# TMS320F280049 register map
Vendor: Texas Instruments; Series: C2000 F28004x; File version: 0.2.0-generated
Registers are 16-bit, read-write, reset 0x0 unless marked. A register's access mark holds for its fields unless they carry their own. Offsets are from the block's base; [hi:lo] are bit positions; {n}, {i} and the like mark numbered series.

## PIECTRLREGS — PIE CTRL Registers
Base 0x000019C0
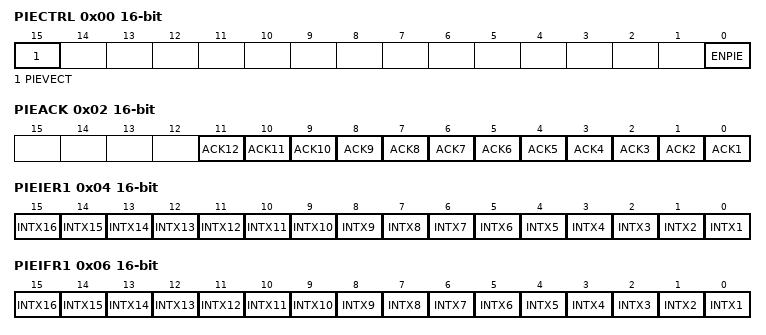
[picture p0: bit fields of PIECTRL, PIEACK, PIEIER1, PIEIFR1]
0x00 PIECTRL — ePIE Control Register
  [15] PIEVECT — PIE Vector Address
  [0] ENPIE — PIE Enable
0x02 PIEACK — Interrupt Acknowledge Register
  [n-1] ACK{n} (n=1..12) — Acknowledge PIE Interrupt Group {n}
0x04 PIEIER1 — Interrupt Group 1 Enable Register
  [15] INTX16 — Enable for Interrupt 1.16
  [14] INTX15 — Enable for Interrupt 1.15
  [13] INTX14 — Enable for Interrupt 1.14
  [12] INTX13 — Enable for Interrupt 1.13
  [11] INTX12 — Enable for Interrupt 1.12
  [10] INTX11 — Enable for Interrupt 1.11
  [9] INTX10 — Enable for Interrupt 1.10
  [8] INTX9 — Enable for Interrupt 1.9
  [7] INTX8 — Enable for Interrupt 1.8
  [6] INTX7 — Enable for Interrupt 1.7
  [5] INTX6 — Enable for Interrupt 1.6
  [4] INTX5 — Enable for Interrupt 1.5
  [3] INTX4 — Enable for Interrupt 1.4
  [2] INTX3 — Enable for Interrupt 1.3
  [1] INTX2 — Enable for Interrupt 1.2
  [0] INTX1 — Enable for Interrupt 1.1
0x06 PIEIFR1 — Interrupt Group 1 Flag Register
  [15] INTX16 — Flag for Interrupt 1.16
  [14] INTX15 — Flag for Interrupt 1.15
  [13] INTX14 — Flag for Interrupt 1.14
  [12] INTX13 — Flag for Interrupt 1.13
  [11] INTX12 — Flag for Interrupt 1.12
  [10] INTX11 — Flag for Interrupt 1.11
  [9] INTX10 — Flag for Interrupt 1.10
  [8] INTX9 — Flag for Interrupt 1.9
  [7] INTX8 — Flag for Interrupt 1.8
  [6] INTX7 — Flag for Interrupt 1.7
  [5] INTX6 — Flag for Interrupt 1.6
  [4] INTX5 — Flag for Interrupt 1.5
  [3] INTX4 — Flag for Interrupt 1.4
  [2] INTX3 — Flag for Interrupt 1.3
  [1] INTX2 — Flag for Interrupt 1.2
  [0] INTX1 — Flag for Interrupt 1.1
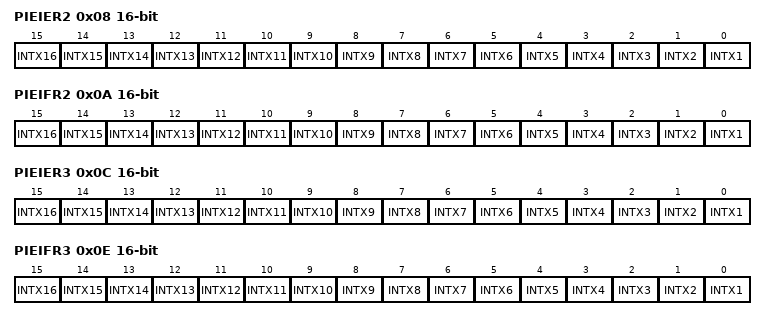
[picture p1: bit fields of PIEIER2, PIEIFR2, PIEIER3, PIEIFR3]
0x08 PIEIER2 — Interrupt Group 2 Enable Register
  [15] INTX16 — Enable for Interrupt 2.16
  [14] INTX15 — Enable for Interrupt 2.15
  [13] INTX14 — Enable for Interrupt 2.14
  [12] INTX13 — Enable for Interrupt 2.13
  [11] INTX12 — Enable for Interrupt 2.12
  [10] INTX11 — Enable for Interrupt 2.11
  [9] INTX10 — Enable for Interrupt 2.10
  [8] INTX9 — Enable for Interrupt 2.9
  [7] INTX8 — Enable for Interrupt 2.8
  [6] INTX7 — Enable for Interrupt 2.7
  [5] INTX6 — Enable for Interrupt 2.6
  [4] INTX5 — Enable for Interrupt 2.5
  [3] INTX4 — Enable for Interrupt 2.4
  [2] INTX3 — Enable for Interrupt 2.3
  [1] INTX2 — Enable for Interrupt 2.2
  [0] INTX1 — Enable for Interrupt 2.1
0x0A PIEIFR2 — Interrupt Group 2 Flag Register
  [15] INTX16 — Flag for Interrupt 2.16
  [14] INTX15 — Flag for Interrupt 2.15
  [13] INTX14 — Flag for Interrupt 2.14
  [12] INTX13 — Flag for Interrupt 2.13
  [11] INTX12 — Flag for Interrupt 2.12
  [10] INTX11 — Flag for Interrupt 2.11
  [9] INTX10 — Flag for Interrupt 2.10
  [8] INTX9 — Flag for Interrupt 2.9
  [7] INTX8 — Flag for Interrupt 2.8
  [6] INTX7 — Flag for Interrupt 2.7
  [5] INTX6 — Flag for Interrupt 2.6
  [4] INTX5 — Flag for Interrupt 2.5
  [3] INTX4 — Flag for Interrupt 2.4
  [2] INTX3 — Flag for Interrupt 2.3
  [1] INTX2 — Flag for Interrupt 2.2
  [0] INTX1 — Flag for Interrupt 2.1
0x0C PIEIER3 — Interrupt Group 3 Enable Register
  [15] INTX16 — Enable for Interrupt 3.16
  [14] INTX15 — Enable for Interrupt 3.15
  [13] INTX14 — Enable for Interrupt 3.14
  [12] INTX13 — Enable for Interrupt 3.13
  [11] INTX12 — Enable for Interrupt 3.12
  [10] INTX11 — Enable for Interrupt 3.11
  [9] INTX10 — Enable for Interrupt 3.10
  [8] INTX9 — Enable for Interrupt 3.9
  [7] INTX8 — Enable for Interrupt 3.8
  [6] INTX7 — Enable for Interrupt 3.7
  [5] INTX6 — Enable for Interrupt 3.6
  [4] INTX5 — Enable for Interrupt 3.5
  [3] INTX4 — Enable for Interrupt 3.4
  [2] INTX3 — Enable for Interrupt 3.3
  [1] INTX2 — Enable for Interrupt 3.2
  [0] INTX1 — Enable for Interrupt 3.1
0x0E PIEIFR3 — Interrupt Group 3 Flag Register
  [15] INTX16 — Flag for Interrupt 3.16
  [14] INTX15 — Flag for Interrupt 3.15
  [13] INTX14 — Flag for Interrupt 3.14
  [12] INTX13 — Flag for Interrupt 3.13
  [11] INTX12 — Flag for Interrupt 3.12
  [10] INTX11 — Flag for Interrupt 3.11
  [9] INTX10 — Flag for Interrupt 3.10
  [8] INTX9 — Flag for Interrupt 3.9
  [7] INTX8 — Flag for Interrupt 3.8
  [6] INTX7 — Flag for Interrupt 3.7
  [5] INTX6 — Flag for Interrupt 3.6
  [4] INTX5 — Flag for Interrupt 3.5
  [3] INTX4 — Flag for Interrupt 3.4
  [2] INTX3 — Flag for Interrupt 3.3
  [1] INTX2 — Flag for Interrupt 3.2
  [0] INTX1 — Flag for Interrupt 3.1
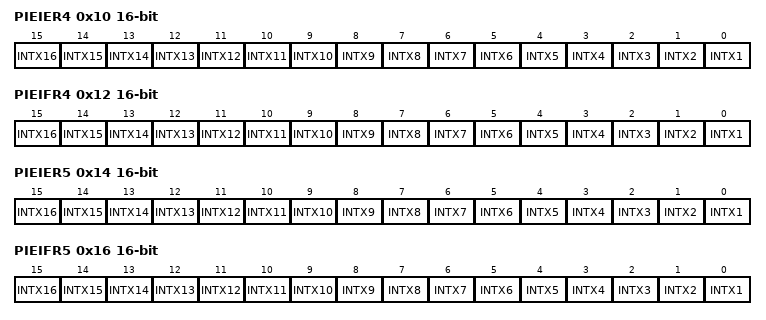
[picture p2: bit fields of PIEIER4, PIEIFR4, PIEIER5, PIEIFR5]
0x10 PIEIER4 — Interrupt Group 4 Enable Register
  [15] INTX16 — Enable for Interrupt 4.16
  [14] INTX15 — Enable for Interrupt 4.15
  [13] INTX14 — Enable for Interrupt 4.14
  [12] INTX13 — Enable for Interrupt 4.13
  [11] INTX12 — Enable for Interrupt 4.12
  [10] INTX11 — Enable for Interrupt 4.11
  [9] INTX10 — Enable for Interrupt 4.10
  [8] INTX9 — Enable for Interrupt 4.9
  [7] INTX8 — Enable for Interrupt 4.8
  [6] INTX7 — Enable for Interrupt 4.7
  [5] INTX6 — Enable for Interrupt 4.6
  [4] INTX5 — Enable for Interrupt 4.5
  [3] INTX4 — Enable for Interrupt 4.4
  [2] INTX3 — Enable for Interrupt 4.3
  [1] INTX2 — Enable for Interrupt 4.2
  [0] INTX1 — Enable for Interrupt 4.1
0x12 PIEIFR4 — Interrupt Group 4 Flag Register
  [15] INTX16 — Flag for Interrupt 4.16
  [14] INTX15 — Flag for Interrupt 4.15
  [13] INTX14 — Flag for Interrupt 4.14
  [12] INTX13 — Flag for Interrupt 4.13
  [11] INTX12 — Flag for Interrupt 4.12
  [10] INTX11 — Flag for Interrupt 4.11
  [9] INTX10 — Flag for Interrupt 4.10
  [8] INTX9 — Flag for Interrupt 4.9
  [7] INTX8 — Flag for Interrupt 4.8
  [6] INTX7 — Flag for Interrupt 4.7
  [5] INTX6 — Flag for Interrupt 4.6
  [4] INTX5 — Flag for Interrupt 4.5
  [3] INTX4 — Flag for Interrupt 4.4
  [2] INTX3 — Flag for Interrupt 4.3
  [1] INTX2 — Flag for Interrupt 4.2
  [0] INTX1 — Flag for Interrupt 4.1
0x14 PIEIER5 — Interrupt Group 5 Enable Register
  [15] INTX16 — Enable for Interrupt 5.16
  [14] INTX15 — Enable for Interrupt 5.15
  [13] INTX14 — Enable for Interrupt 5.14
  [12] INTX13 — Enable for Interrupt 5.13
  [11] INTX12 — Enable for Interrupt 5.12
  [10] INTX11 — Enable for Interrupt 5.11
  [9] INTX10 — Enable for Interrupt 5.10
  [8] INTX9 — Enable for Interrupt 5.9
  [7] INTX8 — Enable for Interrupt 5.8
  [6] INTX7 — Enable for Interrupt 5.7
  [5] INTX6 — Enable for Interrupt 5.6
  [4] INTX5 — Enable for Interrupt 5.5
  [3] INTX4 — Enable for Interrupt 5.4
  [2] INTX3 — Enable for Interrupt 5.3
  [1] INTX2 — Enable for Interrupt 5.2
  [0] INTX1 — Enable for Interrupt 5.1
0x16 PIEIFR5 — Interrupt Group 5 Flag Register
  [15] INTX16 — Flag for Interrupt 5.16
  [14] INTX15 — Flag for Interrupt 5.15
  [13] INTX14 — Flag for Interrupt 5.14
  [12] INTX13 — Flag for Interrupt 5.13
  [11] INTX12 — Flag for Interrupt 5.12
  [10] INTX11 — Flag for Interrupt 5.11
  [9] INTX10 — Flag for Interrupt 5.10
  [8] INTX9 — Flag for Interrupt 5.9
  [7] INTX8 — Flag for Interrupt 5.8
  [6] INTX7 — Flag for Interrupt 5.7
  [5] INTX6 — Flag for Interrupt 5.6
  [4] INTX5 — Flag for Interrupt 5.5
  [3] INTX4 — Flag for Interrupt 5.4
  [2] INTX3 — Flag for Interrupt 5.3
  [1] INTX2 — Flag for Interrupt 5.2
  [0] INTX1 — Flag for Interrupt 5.1
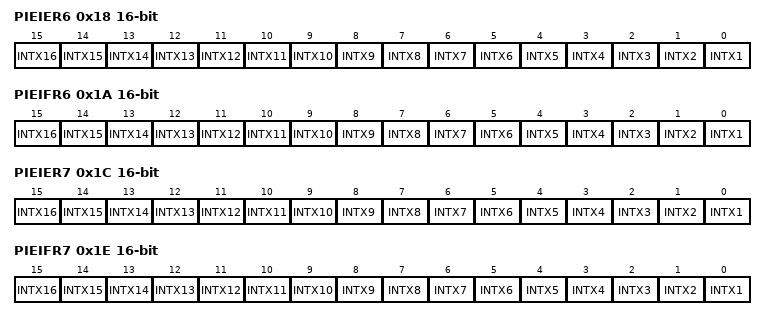
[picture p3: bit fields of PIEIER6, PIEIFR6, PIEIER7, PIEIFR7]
0x18 PIEIER6 — Interrupt Group 6 Enable Register
  [15] INTX16 — Enable for Interrupt 6.16
  [14] INTX15 — Enable for Interrupt 6.15
  [13] INTX14 — Enable for Interrupt 6.14
  [12] INTX13 — Enable for Interrupt 6.13
  [11] INTX12 — Enable for Interrupt 6.12
  [10] INTX11 — Enable for Interrupt 6.11
  [9] INTX10 — Enable for Interrupt 6.10
  [8] INTX9 — Enable for Interrupt 6.9
  [7] INTX8 — Enable for Interrupt 6.8
  [6] INTX7 — Enable for Interrupt 6.7
  [5] INTX6 — Enable for Interrupt 6.6
  [4] INTX5 — Enable for Interrupt 6.5
  [3] INTX4 — Enable for Interrupt 6.4
  [2] INTX3 — Enable for Interrupt 6.3
  [1] INTX2 — Enable for Interrupt 6.2
  [0] INTX1 — Enable for Interrupt 6.1
0x1A PIEIFR6 — Interrupt Group 6 Flag Register
  [15] INTX16 — Flag for Interrupt 6.16
  [14] INTX15 — Flag for Interrupt 6.15
  [13] INTX14 — Flag for Interrupt 6.14
  [12] INTX13 — Flag for Interrupt 6.13
  [11] INTX12 — Flag for Interrupt 6.12
  [10] INTX11 — Flag for Interrupt 6.11
  [9] INTX10 — Flag for Interrupt 6.10
  [8] INTX9 — Flag for Interrupt 6.9
  [7] INTX8 — Flag for Interrupt 6.8
  [6] INTX7 — Flag for Interrupt 6.7
  [5] INTX6 — Flag for Interrupt 6.6
  [4] INTX5 — Flag for Interrupt 6.5
  [3] INTX4 — Flag for Interrupt 6.4
  [2] INTX3 — Flag for Interrupt 6.3
  [1] INTX2 — Flag for Interrupt 6.2
  [0] INTX1 — Flag for Interrupt 6.1
0x1C PIEIER7 — Interrupt Group 7 Enable Register
  [15] INTX16 — Enable for Interrupt 7.16
  [14] INTX15 — Enable for Interrupt 7.15
  [13] INTX14 — Enable for Interrupt 7.14
  [12] INTX13 — Enable for Interrupt 7.13
  [11] INTX12 — Enable for Interrupt 7.12
  [10] INTX11 — Enable for Interrupt 7.11
  [9] INTX10 — Enable for Interrupt 7.10
  [8] INTX9 — Enable for Interrupt 7.9
  [7] INTX8 — Enable for Interrupt 7.8
  [6] INTX7 — Enable for Interrupt 7.7
  [5] INTX6 — Enable for Interrupt 7.6
  [4] INTX5 — Enable for Interrupt 7.5
  [3] INTX4 — Enable for Interrupt 7.4
  [2] INTX3 — Enable for Interrupt 7.3
  [1] INTX2 — Enable for Interrupt 7.2
  [0] INTX1 — Enable for Interrupt 7.1
0x1E PIEIFR7 — Interrupt Group 7 Flag Register
  [15] INTX16 — Flag for Interrupt 7.16
  [14] INTX15 — Flag for Interrupt 7.15
  [13] INTX14 — Flag for Interrupt 7.14
  [12] INTX13 — Flag for Interrupt 7.13
  [11] INTX12 — Flag for Interrupt 7.12
  [10] INTX11 — Flag for Interrupt 7.11
  [9] INTX10 — Flag for Interrupt 7.10
  [8] INTX9 — Flag for Interrupt 7.9
  [7] INTX8 — Flag for Interrupt 7.8
  [6] INTX7 — Flag for Interrupt 7.7
  [5] INTX6 — Flag for Interrupt 7.6
  [4] INTX5 — Flag for Interrupt 7.5
  [3] INTX4 — Flag for Interrupt 7.4
  [2] INTX3 — Flag for Interrupt 7.3
  [1] INTX2 — Flag for Interrupt 7.2
  [0] INTX1 — Flag for Interrupt 7.1
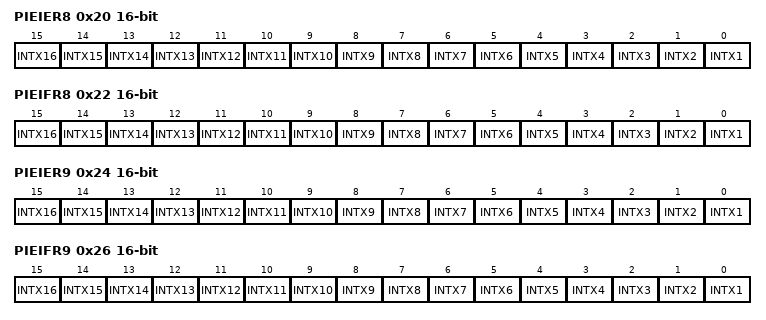
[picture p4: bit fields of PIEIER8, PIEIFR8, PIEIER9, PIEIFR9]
0x20 PIEIER8 — Interrupt Group 8 Enable Register
  [15] INTX16 — Enable for Interrupt 8.16
  [14] INTX15 — Enable for Interrupt 8.15
  [13] INTX14 — Enable for Interrupt 8.14
  [12] INTX13 — Enable for Interrupt 8.13
  [11] INTX12 — Enable for Interrupt 8.12
  [10] INTX11 — Enable for Interrupt 8.11
  [9] INTX10 — Enable for Interrupt 8.10
  [8] INTX9 — Enable for Interrupt 8.9
  [7] INTX8 — Enable for Interrupt 8.8
  [6] INTX7 — Enable for Interrupt 8.7
  [5] INTX6 — Enable for Interrupt 8.6
  [4] INTX5 — Enable for Interrupt 8.5
  [3] INTX4 — Enable for Interrupt 8.4
  [2] INTX3 — Enable for Interrupt 8.3
  [1] INTX2 — Enable for Interrupt 8.2
  [0] INTX1 — Enable for Interrupt 8.1
0x22 PIEIFR8 — Interrupt Group 8 Flag Register
  [15] INTX16 — Flag for Interrupt 8.16
  [14] INTX15 — Flag for Interrupt 8.15
  [13] INTX14 — Flag for Interrupt 8.14
  [12] INTX13 — Flag for Interrupt 8.13
  [11] INTX12 — Flag for Interrupt 8.12
  [10] INTX11 — Flag for Interrupt 8.11
  [9] INTX10 — Flag for Interrupt 8.10
  [8] INTX9 — Flag for Interrupt 8.9
  [7] INTX8 — Flag for Interrupt 8.8
  [6] INTX7 — Flag for Interrupt 8.7
  [5] INTX6 — Flag for Interrupt 8.6
  [4] INTX5 — Flag for Interrupt 8.5
  [3] INTX4 — Flag for Interrupt 8.4
  [2] INTX3 — Flag for Interrupt 8.3
  [1] INTX2 — Flag for Interrupt 8.2
  [0] INTX1 — Flag for Interrupt 8.1
0x24 PIEIER9 — Interrupt Group 9 Enable Register
  [15] INTX16 — Enable for Interrupt 9.16
  [14] INTX15 — Enable for Interrupt 9.15
  [13] INTX14 — Enable for Interrupt 9.14
  [12] INTX13 — Enable for Interrupt 9.13
  [11] INTX12 — Enable for Interrupt 9.12
  [10] INTX11 — Enable for Interrupt 9.11
  [9] INTX10 — Enable for Interrupt 9.10
  [8] INTX9 — Enable for Interrupt 9.9
  [7] INTX8 — Enable for Interrupt 9.8
  [6] INTX7 — Enable for Interrupt 9.7
  [5] INTX6 — Enable for Interrupt 9.6
  [4] INTX5 — Enable for Interrupt 9.5
  [3] INTX4 — Enable for Interrupt 9.4
  [2] INTX3 — Enable for Interrupt 9.3
  [1] INTX2 — Enable for Interrupt 9.2
  [0] INTX1 — Enable for Interrupt 9.1
0x26 PIEIFR9 — Interrupt Group 9 Flag Register
  [15] INTX16 — Flag for Interrupt 9.16
  [14] INTX15 — Flag for Interrupt 9.15
  [13] INTX14 — Flag for Interrupt 9.14
  [12] INTX13 — Flag for Interrupt 9.13
  [11] INTX12 — Flag for Interrupt 9.12
  [10] INTX11 — Flag for Interrupt 9.11
  [9] INTX10 — Flag for Interrupt 9.10
  [8] INTX9 — Flag for Interrupt 9.9
  [7] INTX8 — Flag for Interrupt 9.8
  [6] INTX7 — Flag for Interrupt 9.7
  [5] INTX6 — Flag for Interrupt 9.6
  [4] INTX5 — Flag for Interrupt 9.5
  [3] INTX4 — Flag for Interrupt 9.4
  [2] INTX3 — Flag for Interrupt 9.3
  [1] INTX2 — Flag for Interrupt 9.2
  [0] INTX1 — Flag for Interrupt 9.1
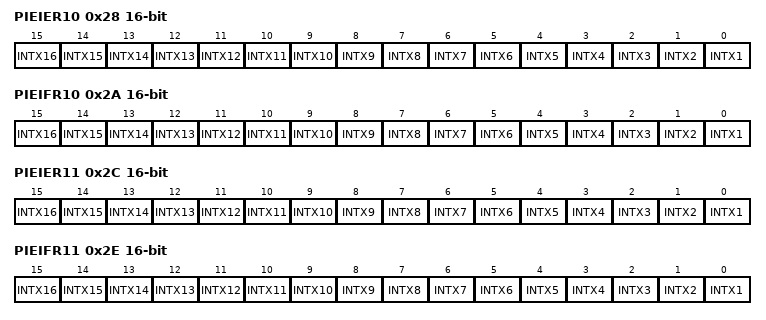
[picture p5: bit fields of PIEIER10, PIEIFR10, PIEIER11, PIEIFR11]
0x28 PIEIER10 — Interrupt Group 10 Enable Register
  [15] INTX16 — Enable for Interrupt 10.16
  [14] INTX15 — Enable for Interrupt 10.15
  [13] INTX14 — Enable for Interrupt 10.14
  [12] INTX13 — Enable for Interrupt 10.13
  [11] INTX12 — Enable for Interrupt 10.12
  [10] INTX11 — Enable for Interrupt 10.11
  [9] INTX10 — Enable for Interrupt 10.10
  [8] INTX9 — Enable for Interrupt 10.9
  [7] INTX8 — Enable for Interrupt 10.8
  [6] INTX7 — Enable for Interrupt 10.7
  [5] INTX6 — Enable for Interrupt 10.6
  [4] INTX5 — Enable for Interrupt 10.5
  [3] INTX4 — Enable for Interrupt 10.4
  [2] INTX3 — Enable for Interrupt 10.3
  [1] INTX2 — Enable for Interrupt 10.2
  [0] INTX1 — Enable for Interrupt 10.1
0x2A PIEIFR10 — Interrupt Group 10 Flag Register
  [15] INTX16 — Flag for Interrupt 10.16
  [14] INTX15 — Flag for Interrupt 10.15
  [13] INTX14 — Flag for Interrupt 10.14
  [12] INTX13 — Flag for Interrupt 10.13
  [11] INTX12 — Flag for Interrupt 10.12
  [10] INTX11 — Flag for Interrupt 10.11
  [9] INTX10 — Flag for Interrupt 10.10
  [8] INTX9 — Flag for Interrupt 10.9
  [7] INTX8 — Flag for Interrupt 10.8
  [6] INTX7 — Flag for Interrupt 10.7
  [5] INTX6 — Flag for Interrupt 10.6
  [4] INTX5 — Flag for Interrupt 10.5
  [3] INTX4 — Flag for Interrupt 10.4
  [2] INTX3 — Flag for Interrupt 10.3
  [1] INTX2 — Flag for Interrupt 10.2
  [0] INTX1 — Flag for Interrupt 10.1
0x2C PIEIER11 — Interrupt Group 11 Enable Register
  [15] INTX16 — Enable for Interrupt 11.16
  [14] INTX15 — Enable for Interrupt 11.15
  [13] INTX14 — Enable for Interrupt 11.14
  [12] INTX13 — Enable for Interrupt 11.13
  [11] INTX12 — Enable for Interrupt 11.12
  [10] INTX11 — Enable for Interrupt 11.11
  [9] INTX10 — Enable for Interrupt 11.10
  [8] INTX9 — Enable for Interrupt 11.9
  [7] INTX8 — Enable for Interrupt 11.8
  [6] INTX7 — Enable for Interrupt 11.7
  [5] INTX6 — Enable for Interrupt 11.6
  [4] INTX5 — Enable for Interrupt 11.5
  [3] INTX4 — Enable for Interrupt 11.4
  [2] INTX3 — Enable for Interrupt 11.3
  [1] INTX2 — Enable for Interrupt 11.2
  [0] INTX1 — Enable for Interrupt 11.1
0x2E PIEIFR11 — Interrupt Group 11 Flag Register
  [15] INTX16 — Flag for Interrupt 11.16
  [14] INTX15 — Flag for Interrupt 11.15
  [13] INTX14 — Flag for Interrupt 11.14
  [12] INTX13 — Flag for Interrupt 11.13
  [11] INTX12 — Flag for Interrupt 11.12
  [10] INTX11 — Flag for Interrupt 11.11
  [9] INTX10 — Flag for Interrupt 11.10
  [8] INTX9 — Flag for Interrupt 11.9
  [7] INTX8 — Flag for Interrupt 11.8
  [6] INTX7 — Flag for Interrupt 11.7
  [5] INTX6 — Flag for Interrupt 11.6
  [4] INTX5 — Flag for Interrupt 11.5
  [3] INTX4 — Flag for Interrupt 11.4
  [2] INTX3 — Flag for Interrupt 11.3
  [1] INTX2 — Flag for Interrupt 11.2
  [0] INTX1 — Flag for Interrupt 11.1
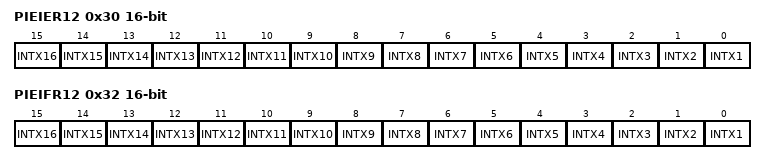
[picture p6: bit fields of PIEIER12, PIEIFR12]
0x30 PIEIER12 — Interrupt Group 12 Enable Register
  [15] INTX16 — Enable for Interrupt 12.16
  [14] INTX15 — Enable for Interrupt 12.15
  [13] INTX14 — Enable for Interrupt 12.14
  [12] INTX13 — Enable for Interrupt 12.13
  [11] INTX12 — Enable for Interrupt 12.12
  [10] INTX11 — Enable for Interrupt 12.11
  [9] INTX10 — Enable for Interrupt 12.10
  [8] INTX9 — Enable for Interrupt 12.9
  [7] INTX8 — Enable for Interrupt 12.8
  [6] INTX7 — Enable for Interrupt 12.7
  [5] INTX6 — Enable for Interrupt 12.6
  [4] INTX5 — Enable for Interrupt 12.5
  [3] INTX4 — Enable for Interrupt 12.4
  [2] INTX3 — Enable for Interrupt 12.3
  [1] INTX2 — Enable for Interrupt 12.2
  [0] INTX1 — Enable for Interrupt 12.1
0x32 PIEIFR12 — Interrupt Group 12 Flag Register
  [15] INTX16 — Flag for Interrupt 12.16
  [14] INTX15 — Flag for Interrupt 12.15
  [13] INTX14 — Flag for Interrupt 12.14
  [12] INTX13 — Flag for Interrupt 12.13
  [11] INTX12 — Flag for Interrupt 12.12
  [10] INTX11 — Flag for Interrupt 12.11
  [9] INTX10 — Flag for Interrupt 12.10
  [8] INTX9 — Flag for Interrupt 12.9
  [7] INTX8 — Flag for Interrupt 12.8
  [6] INTX7 — Flag for Interrupt 12.7
  [5] INTX6 — Flag for Interrupt 12.6
  [4] INTX5 — Flag for Interrupt 12.5
  [3] INTX4 — Flag for Interrupt 12.4
  [2] INTX3 — Flag for Interrupt 12.3
  [1] INTX2 — Flag for Interrupt 12.2
  [0] INTX1 — Flag for Interrupt 12.1
